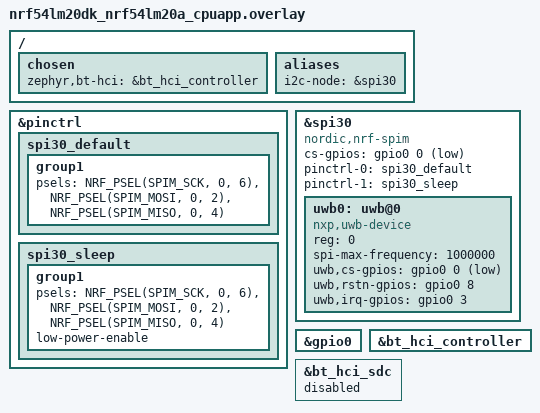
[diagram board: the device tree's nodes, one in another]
/*
 * Copyright (c) 2026 Nordic Semiconductor ASA
 *
 * SPDX-License-Identifier: LicenseRef-Nordic-5-Clause
 */

&pinctrl {
	spi30_default: spi30_default {
		group1 {
			psels = <NRF_PSEL(SPIM_SCK, 0, 6)>,
				<NRF_PSEL(SPIM_MOSI, 0, 2)>,
				<NRF_PSEL(SPIM_MISO, 0, 4)>;
		};
	};

	spi30_sleep: spi30_sleep {
		group1 {
			psels = <NRF_PSEL(SPIM_SCK, 0, 6)>,
				<NRF_PSEL(SPIM_MOSI, 0, 2)>,
				<NRF_PSEL(SPIM_MISO, 0, 4)>;
			low-power-enable;
		};
	};
};

&spi30 {
	compatible = "nordic,nrf-spim";
	status = "okay";
	cs-gpios = <&gpio0 0 GPIO_ACTIVE_LOW>;
	pinctrl-0 = <&spi30_default>;
	pinctrl-1 = <&spi30_sleep>;
	pinctrl-names = "default", "sleep";
	#address-cells = <1>;
	#size-cells = <0>;

	uwb0: uwb@0 {
		compatible = "nxp,uwb-device";
		reg = <0>;
		spi-max-frequency = <1000000>;
		uwb,cs-gpios = <&gpio0 0 GPIO_ACTIVE_LOW>;
		uwb,rstn-gpios = <&gpio0 8 (GPIO_ACTIVE_HIGH | GPIO_PULL_UP)>;
		uwb,irq-gpios = <&gpio0 3 GPIO_ACTIVE_HIGH>;
	};
};

&gpio0 {
	status = "okay";
};

&bt_hci_controller {
	status = "okay";
};

&bt_hci_sdc {
	status = "disabled";
};

/ {
	chosen {
		zephyr,bt-hci = &bt_hci_controller;
	};

	aliases {
		/* The NXP Virgo board shim compiles an unused I2C helper even for SPI builds. */
		i2c-node = &spi30;
	};
};
